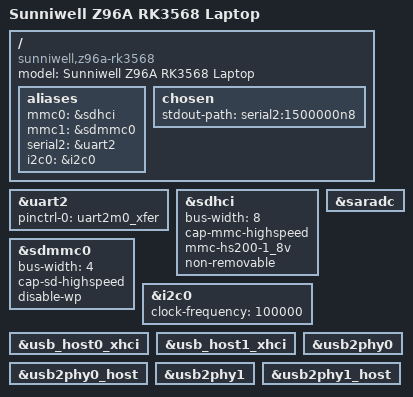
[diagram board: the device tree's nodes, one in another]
// SPDX-License-Identifier: (GPL-2.0+ OR MIT)
/*
 * Sunniwell Z96A RK3568 Laptop — minimal U-Boot DT
 * Linux still boots with Armbian kernel DTB for full peripherals.
 */

/dts-v1/;

#include <dt-bindings/gpio/gpio.h>
#include <dt-bindings/pinctrl/rockchip.h>
#include "rk3568.dtsi"

/ {
	model = "Sunniwell Z96A RK3568 Laptop";
	compatible = "sunniwell,z96a-rk3568", "rockchip,rk3568";

	aliases {
		mmc0 = &sdhci;
		mmc1 = &sdmmc0;
		serial2 = &uart2;
		i2c0 = &i2c0;
	};

	chosen {
		stdout-path = "serial2:1500000n8";
	};
};

&uart2 {
	pinctrl-0 = <&uart2m0_xfer>;
	status = "okay";
};

&sdhci {
	bus-width = <8>;
	cap-mmc-highspeed;
	mmc-hs200-1_8v;
	non-removable;
	status = "okay";
};

&sdmmc0 {
	bus-width = <4>;
	cap-sd-highspeed;
	disable-wp;
	status = "okay";
};

/* RK809 PMIC + HUSB311 on I2C0 (V2) — enable bus for U-Boot i2c probe */
&i2c0 {
	status = "okay";
	clock-frequency = <100000>;
};

&saradc {
	status = "okay";
};

&usb_host0_xhci {
	status = "okay";
};

&usb_host1_xhci {
	status = "okay";
};

&usb2phy0 {
	status = "okay";
};

&usb2phy0_host {
	status = "okay";
};

&usb2phy1 {
	status = "okay";
};

&usb2phy1_host {
	status = "okay";
};
